VERSION ""

NS_ :

BS_:

BU_: XXX

BO_ 85 CID_XOZHAS: 8 XXX
 SG_ sig_oaqpoa : 40|1@1+ (1,0) [0|1] "" XXX
 SG_ sig_rqtnos : 56|8@1+ (1,0) [0|255] "" XXX

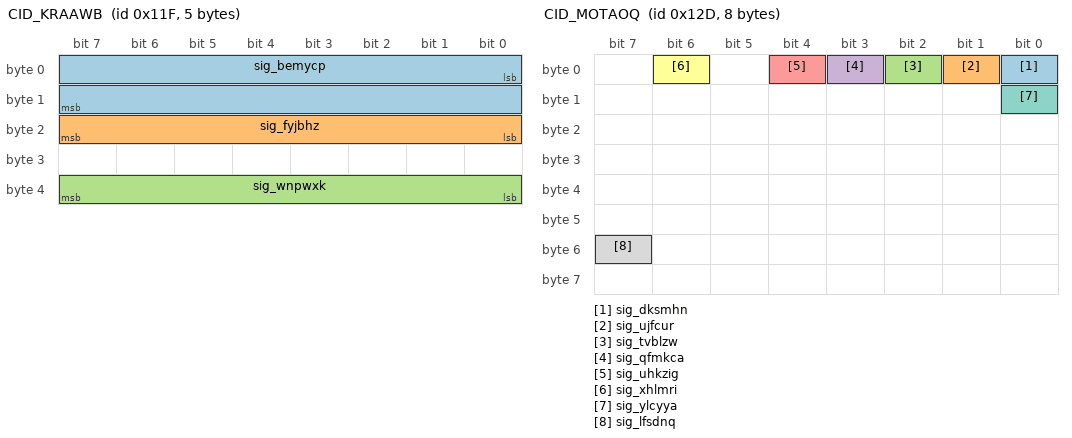
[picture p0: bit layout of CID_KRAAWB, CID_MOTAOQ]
BO_ 287 CID_KRAAWB: 5 XXX
 SG_ sig_bemycp : 0|16@1- (0.1,0) [-450|450] "" XXX
 SG_ sig_fyjbhz : 16|8@1+ (4,0) [0|1020] "" XXX
 SG_ sig_wnpwxk : 32|8@1+ (1,0) [0|255] "" XXX

BO_ 289 CID_BZIYDJ: 8 XXX
 SG_ sig_yxflza : 0|12@1+ (1,0) [0|255] "" XXX

BO_ 301 CID_MOTAOQ: 8 XXX
 SG_ sig_dksmhn : 0|1@0+ (1,0) [0|1] "" XXX
 SG_ sig_ujfcur : 1|1@0+ (1,0) [0|1] "" XXX
 SG_ sig_tvblzw : 2|1@0+ (1,0) [0|1] "" XXX
 SG_ sig_qfmkca : 3|1@0+ (1,0) [0|1] "" XXX
 SG_ sig_uhkzig : 4|1@0+ (1,0) [0|1] "" XXX
 SG_ sig_xhlmri : 6|1@0+ (1,0) [0|1] "" XXX
 SG_ sig_ylcyya : 8|1@0+ (1,0) [0|1] "" XXX
 SG_ sig_lfsdnq : 55|1@0+ (1,0) [0|1] "" XXX

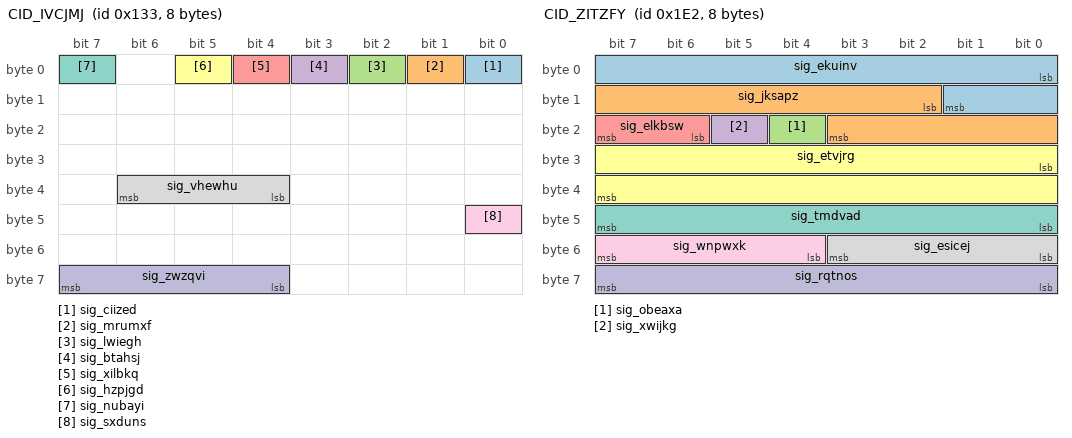
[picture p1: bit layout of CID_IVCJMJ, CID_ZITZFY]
BO_ 307 CID_IVCJMJ: 8 XXX
 SG_ sig_ciized : 0|1@0+ (1,0) [0|1] "" XXX
 SG_ sig_mrumxf : 1|1@1+ (1,0) [0|1] "" XXX
 SG_ sig_lwiegh : 2|1@1+ (1,0) [0|1] "" XXX
 SG_ sig_btahsj : 3|1@1+ (1,0) [0|1] "" XXX
 SG_ sig_xilbkq : 4|1@0+ (1,0) [0|1] "" XXX
 SG_ sig_hzpjgd : 5|1@0+ (1,0) [0|1] "" XXX
 SG_ sig_nubayi : 7|1@0+ (1,0) [0|1] "" XXX
 SG_ sig_vhewhu : 36|3@1+ (1,0) [0|7] "" XXX
 SG_ sig_sxduns : 40|1@0+ (1,0) [0|1] "" XXX
 SG_ sig_zwzqvi : 63|4@0+ (1,0) [0|15] "" XXX

BO_ 482 CID_ZITZFY: 8 XXX
 SG_ sig_ekuinv : 0|10@1- (0.01,0) [0|5] "" XXX
 SG_ sig_jksapz : 10|10@1- (0.01,0) [-5|0] "" XXX
 SG_ sig_obeaxa : 20|1@0+ (1,0) [0|1] "" XXX
 SG_ sig_xwijkg : 21|1@0+ (1,0) [0|1] "" XXX
 SG_ sig_elkbsw : 22|2@1+ (1,0) [0|1] "" XXX
 SG_ sig_etvjrg : 24|16@1- (0.1,0) [-780|779.9] "" XXX
 SG_ sig_tmdvad : 47|8@0+ (1,0) [0|255] "" XXX
 SG_ sig_esicej : 48|4@1+ (1,0) [0|15] "" XXX
 SG_ sig_wnpwxk : 52|4@1+ (1,0) [0|15] "" XXX
 SG_ sig_rqtnos : 56|8@1+ (1,0) [0|255] "" XXX

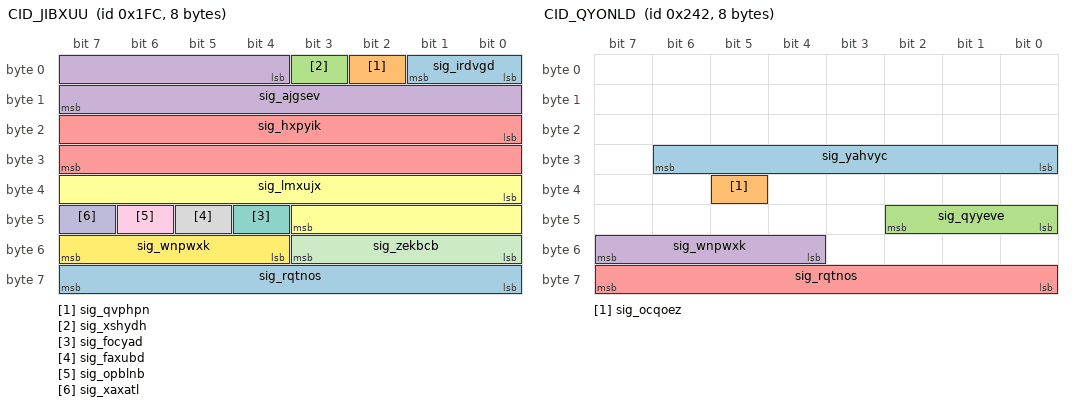
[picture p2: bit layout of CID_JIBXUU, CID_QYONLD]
BO_ 508 CID_JIBXUU: 8 XXX
 SG_ sig_irdvgd : 0|2@1+ (1,0) [0|1] "" XXX
 SG_ sig_qvphpn : 2|1@1+ (1,0) [0|1] "" XXX
 SG_ sig_xshydh : 3|1@0+ (1,0) [0|1] "" XXX
 SG_ sig_ajgsev : 4|12@1- (1,0) [-2048|2047] "" XXX
 SG_ sig_hxpyik : 16|16@1- (0.1,0) [-780|779.9] "Deg" XXX
 SG_ sig_lmxujx : 32|12@1- (0.01,0) [0|63] "" XXX
 SG_ sig_focyad : 44|1@0+ (1,0) [0|1] "" XXX
 SG_ sig_faxubd : 45|1@1+ (1,0) [0|255] "" XXX
 SG_ sig_opblnb : 46|1@1+ (1,0) [0|1] "" XXX
 SG_ sig_xaxatl : 47|1@0+ (1,0) [0|3] "" XXX
 SG_ sig_zekbcb : 48|4@1+ (1,0) [0|15] "" XXX
 SG_ sig_wnpwxk : 52|4@1+ (1,0) [0|15] "" XXX
 SG_ sig_rqtnos : 56|8@1+ (1,0) [0|255] "" XXX

BO_ 578 CID_QYONLD: 8 XXX
 SG_ sig_yahvyc : 30|7@0+ (1,0) [0|127] "" XXX
 SG_ sig_ocqoez : 37|1@0+ (1,0) [0|1] "" XXX
 SG_ sig_qyyeve : 40|3@1+ (1,0) [0|7] "" XXX
 SG_ sig_wnpwxk : 55|4@0+ (1,0) [0|15] "" XXX
 SG_ sig_rqtnos : 56|8@1+ (1,0) [0|255] "" XXX

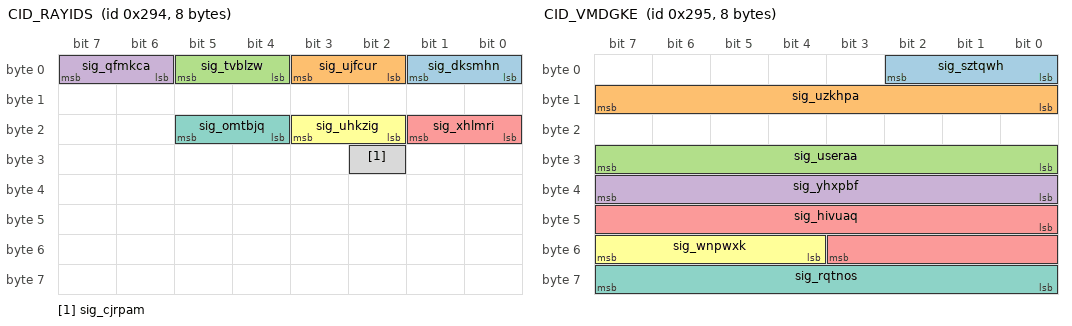
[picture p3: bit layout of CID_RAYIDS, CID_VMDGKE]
BO_ 660 CID_RAYIDS: 8 XXX
 SG_ sig_dksmhn : 1|2@0+ (1,0) [0|3] "" XXX
 SG_ sig_ujfcur : 3|2@0+ (1,0) [0|3] "" XXX
 SG_ sig_tvblzw : 5|2@0+ (1,0) [0|3] "" XXX
 SG_ sig_qfmkca : 7|2@0+ (1,0) [0|3] "" XXX
 SG_ sig_xhlmri : 17|2@0+ (1,0) [0|3] "" XXX
 SG_ sig_uhkzig : 19|2@0+ (1,0) [0|3] "" XXX
 SG_ sig_omtbjq : 21|2@0+ (1,0) [0|3] "" XXX
 SG_ sig_cjrpam : 26|1@0+ (1,0) [0|1] "" XXX

BO_ 661 CID_VMDGKE: 8 XXX
 SG_ sig_sztqwh : 2|3@0+ (1,0) [0|7] "" XXX
 SG_ sig_uzkhpa : 15|8@0+ (1,0) [0|255] "" XXX
 SG_ sig_useraa : 31|8@0+ (1,0) [0|255] "" XXX
 SG_ sig_yhxpbf : 32|8@1+ (1,0) [0|255] "" XXX
 SG_ sig_hivuaq : 40|12@1+ (1,0) [0|255] "" XXX
 SG_ sig_wnpwxk : 52|4@1+ (1,0) [0|15] "" XXX
 SG_ sig_rqtnos : 63|8@0+ (1,0) [0|255] "" XXX

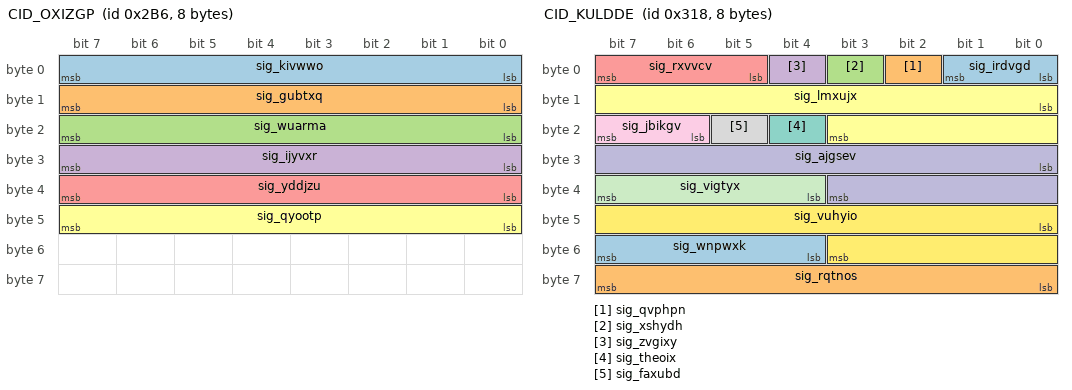
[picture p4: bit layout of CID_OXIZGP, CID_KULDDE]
BO_ 694 CID_OXIZGP: 8 XXX
 SG_ sig_kivwwo : 7|8@0+ (1,0) [0|255] "" XXX
 SG_ sig_gubtxq : 15|8@0+ (1,0) [0|255] "" XXX
 SG_ sig_wuarma : 23|8@0+ (1,0) [0|255] "" XXX
 SG_ sig_ijyvxr : 31|8@0+ (1,0) [0|255] "" XXX
 SG_ sig_yddjzu : 39|8@0+ (1,0) [0|255] "" XXX
 SG_ sig_qyootp : 47|8@0+ (1,0) [0|255] "" XXX

BO_ 790 CID_OCNOVJ: 8 XXX
 SG_ sig_gfaxbb : 3|4@0+ (1,0) [0|1] "" XXX
 SG_ sig_vahrtm : 4|2@1+ (1,0) [0|3] "" XXX
 SG_ sig_vmfjbe : 6|2@1+ (1,0) [0|3] "" XXX
 SG_ sig_mnhmlq : 8|2@1+ (1,0) [0|3] "" XXX
 SG_ sig_nysvqc : 10|1@1+ (1,0) [0|1] "" XXX
 SG_ sig_exvxub : 11|4@1+ (1,0) [0|1] "" XXX
 SG_ sig_aekitu : 15|1@0+ (1,0) [0|1] "" XXX
 SG_ sig_etvjrg : 16|11@1- (1,0) [-1024|1023] "" XXX
 SG_ sig_obeaxa : 27|1@1+ (1,0) [0|1] "" XXX
 SG_ sig_xwijkg : 28|1@1+ (1,0) [0|3] "" XXX
 SG_ sig_anlfzs : 29|1@0+ (1,0) [0|1] "" XXX
 SG_ sig_eqcedw : 30|1@0+ (1,0) [0|1] "" XXX
 SG_ sig_rnnmbw : 31|1@0+ (1,0) [0|1] "" XXX
 SG_ sig_sqkwai : 32|2@1+ (1,0) [0|3] "" XXX
 SG_ sig_hsbzgp : 34|2@1+ (1,0) [0|3] "" XXX
 SG_ sig_eaxvwk : 36|4@1+ (1,0) [0|3] "" XXX
 SG_ sig_jiprpj : 40|8@1+ (5,-5) [-5|1270] "" XXX
 SG_ sig_ueguhw : 49|2@0+ (1,0) [0|3] "" XXX
 SG_ sig_cfigpf : 51|2@0+ (1,0) [0|3] "" XXX
 SG_ sig_wnpwxk : 52|4@1+ (1,0) [0|15] "" XXX
 SG_ sig_rqtnos : 56|8@1+ (1,0) [0|15] "" XXX

BO_ 792 CID_KULDDE: 8 XXX
 SG_ sig_irdvgd : 0|2@1+ (1,0) [0|1] "" XXX
 SG_ sig_qvphpn : 2|1@1+ (1,0) [0|1] "" XXX
 SG_ sig_xshydh : 3|1@1+ (1,0) [0|1] "" XXX
 SG_ sig_zvgixy : 4|1@1+ (1,0) [0|1] "" XXX
 SG_ sig_rxvvcv : 5|3@1+ (1,0) [0|1] "" XXX
 SG_ sig_lmxujx : 8|12@1- (1,0) [-2048|2047] "" XXX
 SG_ sig_theoix : 20|1@1+ (1,0) [0|1] "" XXX
 SG_ sig_faxubd : 21|1@1+ (1,0) [0|1] "" XXX
 SG_ sig_jbikgv : 22|2@1+ (1,0) [0|15] "" XXX
 SG_ sig_ajgsev : 24|12@1- (1,0) [-2048|2047] "" XXX
 SG_ sig_vigtyx : 36|4@1+ (1,0) [0|15] "" XXX
 SG_ sig_vuhyio : 40|12@1+ (1,0) [0|4095] "" XXX
 SG_ sig_wnpwxk : 52|4@1+ (1,0) [0|15] "" XXX
 SG_ sig_rqtnos : 56|8@1+ (1,0) [0|255] "" XXX

BO_ 813 CID_PCLAVQ: 8 XXX
 SG_ sig_rwnnss : 0|9@1+ (0.5,0) [0|255.5] "" XXX
 SG_ sig_onqkce : 9|1@1+ (1,0) [0|1] "" XXX
 SG_ sig_dajpbd : 10|3@1+ (1,0) [0|7] "" XXX
 SG_ sig_slnvlb : 13|3@1+ (1,0) [0|7] "" XXX
 SG_ sig_bzfrkx : 16|1@1+ (1,0) [0|1] "" XXX
 SG_ sig_opswtb : 17|1@1+ (1,0) [0|1] "" XXX
 SG_ sig_xshydh : 18|1@1+ (1,0) [0|1] "" XXX
 SG_ sig_zfizxm : 19|3@1+ (1,0) [0|1] "" XXX
 SG_ sig_heycwm : 22|1@0+ (1,0) [0|1] "" XXX
 SG_ sig_irjbsr : 23|1@0+ (1,0) [0|1] "" XXX
 SG_ sig_mnhmlq : 24|1@1+ (1,0) [0|1] "" XXX
 SG_ sig_tpyiol : 25|7@1+ (1,0) [0|127] "" XXX
 SG_ sig_ccvavx : 32|4@1+ (1,0) [0|15] "" XXX
 SG_ sig_shcext : 36|12@1+ (1,0) [0|4095] "" XXX
 SG_ sig_wnpwxk : 48|4@1+ (1,0) [0|15] "" XXX
 SG_ sig_iesjjp : 55|4@0+ (1,0) [0|15] "" XXX
 SG_ sig_rqtnos : 56|8@1+ (1,0) [0|255] "" XXX

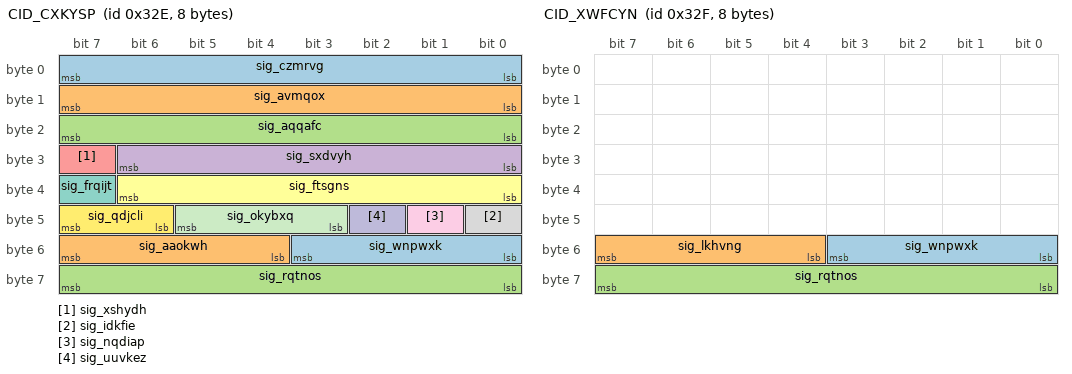
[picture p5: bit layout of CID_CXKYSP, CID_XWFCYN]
BO_ 814 CID_CXKYSP: 8 XXX
 SG_ sig_czmrvg : 0|8@1+ (0.05,-5) [-100|155] "" XXX
 SG_ sig_avmqox : 8|8@1+ (0.05,-5) [0|1.26] "" XXX
 SG_ sig_aqqafc : 16|8@1+ (0.05,-5) [0|1.26] "" XXX
 SG_ sig_sxdvyh : 24|7@1+ (0.2,0) [0|12.7] "" XXX
 SG_ sig_xshydh : 31|1@0+ (1,0) [0|1] "" XXX
 SG_ sig_ftsgns : 32|7@1+ (0.2,-16) [0|12.7] "" XXX
 SG_ sig_frqijt : 39|1@0+ (1,0) [0|1] "" XXX
 SG_ sig_idkfie : 40|1@0+ (1,0) [0|1] "" XXX
 SG_ sig_nqdiap : 41|1@0+ (1,0) [0|1] "" XXX
 SG_ sig_uuvkez : 42|1@1+ (1,0) [0|3] "" XXX
 SG_ sig_okybxq : 45|3@0+ (1,0) [0|1] "" XXX
 SG_ sig_qdjcli : 46|2@1+ (1,0) [0|3] "" XXX
 SG_ sig_wnpwxk : 48|4@1+ (1,0) [0|15] "" XXX
 SG_ sig_aaokwh : 55|4@0+ (1,0) [0|15] "" XXX
 SG_ sig_rqtnos : 56|8@1+ (1,0) [0|255] "" XXX

BO_ 815 CID_XWFCYN: 8 XXX
 SG_ sig_wnpwxk : 48|4@1+ (1,0) [0|15] "" XXX
 SG_ sig_lkhvng : 55|4@0+ (1,0) [0|15] "" XXX
 SG_ sig_rqtnos : 56|8@1+ (1,0) [0|255] "" XXX

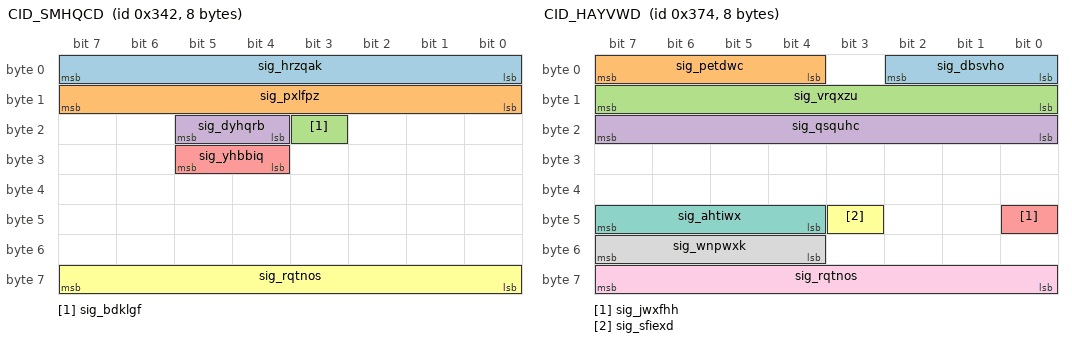
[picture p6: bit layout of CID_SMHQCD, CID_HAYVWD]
BO_ 834 CID_SMHQCD: 8 XXX
 SG_ sig_hrzqak : 0|8@1+ (0.01,0) [0|2.55] "" XXX
 SG_ sig_pxlfpz : 8|8@1+ (0.01,0) [0|2.55] "" XXX
 SG_ sig_bdklgf : 19|1@1+ (1,0) [0|1] "" XXX
 SG_ sig_dyhqrb : 20|2@1+ (1,0) [0|255] "" XXX
 SG_ sig_yhbbiq : 28|2@1+ (1,0) [0|1] "" XXX
 SG_ sig_rqtnos : 56|8@1+ (1,0) [0|255] "" XXX

 BO_ 884 CID_HAYVWD: 8 MRR
 SG_ sig_dbsvho : 2|3@0+ (1,0) [0|3] "" MRR
 SG_ sig_petdwc : 7|4@0+ (1,0) [0|15] "" MRR
 SG_ sig_vrqxzu : 15|8@0+ (0.1,-12) [0|255] "" MRR
 SG_ sig_qsquhc : 23|8@0+ (1,-100) [0|255] "" MRR
 SG_ sig_jwxfhh : 40|1@0+ (1,0) [0|3] "" MRR
 SG_ sig_sfiexd : 43|1@0+ (1,0) [0|1] "" XXX
 SG_ sig_ahtiwx : 44|4@1+ (1,0) [0|15] "" XXX
 SG_ sig_wnpwxk : 52|4@1+ (1,0) [0|15] "" MRR
 SG_ sig_rqtnos : 56|8@1+ (1,0) [0|255] "" MRR

BO_ 944 CID_WGUSGA: 8 XXX
 SG_ sig_ehctak : 1|2@0+ (1,0) [0|3] "" XXX
 SG_ sig_zmeeph : 2|1@0+ (1,0) [0|1] "" XXX
 SG_ sig_yxxqwy : 4|2@0+ (1,0) [0|3] "" XXX
 SG_ sig_hfmovf : 5|1@0+ (1,0) [0|1] "" XXX
 SG_ sig_flcubs : 6|1@0+ (1,0) [0|1] "" XXX
 SG_ sig_zccwbm : 7|1@0+ (1,0) [0|1] "" XXX
 SG_ sig_awkccf : 8|1@0+ (1,0) [0|1] "" XXX
 SG_ sig_edgciw : 11|3@0+ (1,0) [0|7] "" XXX
 SG_ sig_amjxrq : 12|1@0+ (1,0) [0|1] "" XXX
 SG_ sig_qlbtag : 14|2@0+ (1,0) [0|3] "" XXX
 SG_ sig_ccifan : 15|1@0+ (1,0) [0|1] "" XXX
 SG_ sig_pqwlzi : 16|1@0+ (1,0) [0|1] "" XXX
 SG_ sig_ulmrfr : 18|2@0+ (1,0) [0|3] "" XXX
 SG_ sig_gvlhuu : 19|1@0+ (1,0) [0|1] "" XXX
 SG_ sig_brzfzh : 23|4@0+ (1,0) [0|15] "" XXX
 SG_ sig_tzivpz : 24|28@1+ (1,0) [0|268435455] "" XXX
 SG_ sig_wnpwxk : 52|4@1+ (1,0) [0|15] "" XXX
 SG_ sig_rqtnos : 56|8@1+ (1,0) [0|255] "" XXX

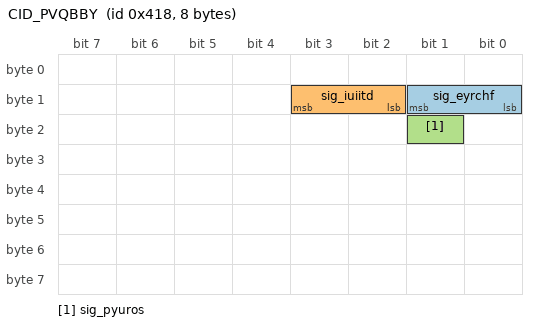
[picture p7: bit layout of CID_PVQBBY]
BO_ 1048 CID_PVQBBY: 8 XXX
 SG_ sig_eyrchf : 9|2@0+ (1,0) [0|1] "" XXX
 SG_ sig_iuiitd : 11|2@0+ (1,0) [0|1] "" XXX
 SG_ sig_pyuros : 17|1@0+ (1,0) [0|1] "" XXX

VAL_ 578 sig_qyyeve 4 "D" 2 "R" 3 "N" 1 "P";
VAL_ 790 sig_gfaxbb 11 "AutoFullBeamActive" 2 "AutoFullBeamInactive";
VAL_ 790 sig_vahrtm 0 "GRAY" 1 "GREEN" 2 "YELLOW" 3 "RED";
VAL_ 790 sig_vmfjbe 3 "ALARM_AND_LKA" 2 "LKA" 1 "ALARM" 0 "DISABLE";
VAL_ 790 sig_hsbzgp 0 "GRAY" 1 "GREEN" 2 "YELLOW" 3 "RED";
VAL_ 790 sig_ueguhw 0 "VIBRATION" 1 "AUDIO" 2 "AUDIO_AND_VIBRATION";
VAL_ 792 sig_irdvgd 0 "NotReady" 1 "Ready" 2 "Active" 3 "TemporaryFail";
VAL_ 813 sig_dajpbd 4 "4BAR" 3 "3BAR" 2 "2BAR" 1 "1BAR";
VAL_ 813 sig_zfizxm 0 "OFF" 2 "ACC_ON" 3 "ACC_ACTIVE" 5 "FORCE_ACCEL" 7 "ERROR";
VAL_ 813 sig_tpyiol 36 "ACC_ERROR" 22 "OVERRIDE" 12 "ENGAGE" 8 "DISENGAGE" 20 "ACC_ON" 32 "ACC_OFF" 48 "CHECK_GEAR_D" 16 "FORCE_ACCEL" 0 "NONE";
VAL_ 814 sig_okybxq 0 "Off" 1 "Passive" 2 "StandBy" 3 "ActiveControl" 4 "BrakeOnly" 5 "Override" 6 "Standstill" 7 "Failure";
VAL_ 814 sig_qdjcli 0 "Softoff" 1 "Fastoff" 2 "Immediateoff" 3 "Initial";
VAL_ 834 sig_dyhqrb 2 "SPORT" 1 "ECO" 0 "SNOW";
VAL_ 834 sig_yhbbiq 3 "HEV" 2 "FORCE_EV" 1 "EV";
VAL_ 944 sig_yxxqwy 0 "NOTPRESSED" 1 "DOWN_SETSPEED" 3 "UP_RESETSPEED";
